AUTOSAR XML (schema 4-3-0)
package /App_ADC
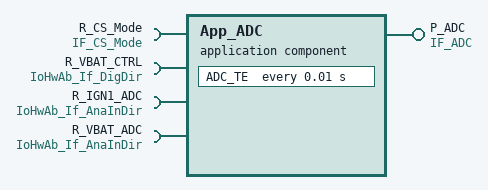
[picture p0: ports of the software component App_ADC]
  application sw component type App_ADC
    provide port P_ADC: nonqueued-sender-com-spec=ADC_STR, provided-interface=IF_ADC
    4 x require port:
      R_CS_Mode: required-com-specs=[ModeInit, NvMInit, ApplicationInit], required-interface=IF_CS_Mode
      R_VBAT_CTRL: client-com-spec=WriteDirect, required-interface=IoHwAb_If_DigDir
      R_IGN1_ADC: client-com-spec=ReadDirect, required-interface=IoHwAb_If_AnaInDir
      R_VBAT_ADC: client-com-spec=ReadDirect, required-interface=IoHwAb_If_AnaInDir
    behavior InternalBehavior: data-type-mapping=DataTypeMappingSet_WPC
      timing event TE_ADC_TE: start-on-event=ADC_TE, period=0.01
      runnable ADC_TE: symbol=ADC_TE_Runnable
        data-send-points:
          access DSP_ADC_TE_P_ADC_Data: accessed-variable=P_ADC.ADC_STR, scope=COMMUNICATION-INTER-ECU
        6 x sync call:
          SSCP_ADC_TE_R_CS_Mode_ApplicationInit: operation=R_CS_Mode.ApplicationInit
          SSCP_ADC_TE_R_CS_Mode_ModeInit: operation=R_CS_Mode.ModeInit
          SSCP_ADC_TE_R_CS_Mode_NvMInit: operation=R_CS_Mode.NvMInit
          SSCP_ADC_TE_R_VBAT_CTRL_WriteDirect: operation=R_VBAT_CTRL.WriteDirect
          SSCP_ADC_TE_R_IGN1_ADC_ReadDirect: operation=R_IGN1_ADC.ReadDirect
          SSCP_ADC_TE_R_VBAT_ADC_ReadDirect: operation=R_VBAT_ADC.ReadDirect
  sender receiver interface IF_ADC  # NFC SWC Output
    data ADC_STR: type=IDT_ADC_STR
